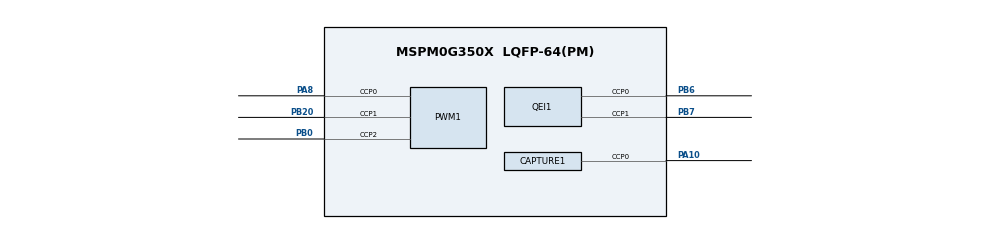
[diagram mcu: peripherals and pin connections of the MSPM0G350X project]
/**
 * @cliArgs --device "MSPM0G350X" --part "Default" --package "LQFP-64(PM)" --product "mspm0_sdk@2.06.00.05"
 * @versions {"tool":"1.21.0+3721"}
 */

/**
 * Import the modules used in this configuration.
 */
const CAPTURE  = scripting.addModule("/ti/driverlib/CAPTURE", {}, false);
const CAPTURE1 = CAPTURE.addInstance();
const GPIO     = scripting.addModule("/ti/driverlib/GPIO", {}, false);
const GPIO1    = GPIO.addInstance();
const GPIO2    = GPIO.addInstance();
const GPIO3    = GPIO.addInstance();
const GPIO4    = GPIO.addInstance();
const PWM      = scripting.addModule("/ti/driverlib/PWM", {}, false);
const PWM1     = PWM.addInstance();
const QEI      = scripting.addModule("/ti/driverlib/QEI", {}, false);
const QEI1     = QEI.addInstance();
const SYSCTL   = scripting.addModule("/ti/driverlib/SYSCTL");
const TIMER    = scripting.addModule("/ti/driverlib/TIMER", {}, false);
const TIMER1   = TIMER.addInstance();

/**
 * Write custom configuration values to the imported modules.
 */
CAPTURE1.$name                       = "CAPTURE_0";
CAPTURE1.multi_countMode             = "DL_TIMER_COUNT_MODE_UP_DOWN";
CAPTURE1.ccIndexMulti                = [0];
CAPTURE1.multi_ch0_input_mode        = "DL_TIMER_CC_IN_SEL_TRIG";
CAPTURE1.multi_ch0_captEdgeDetection = "DL_TIMER_CC_CCOND_TRIG_EDGE";
CAPTURE1.captMode                    = "PERIOD_CAPTURE_UP";
CAPTURE1.captEdgeDetection           = "EDGE";
CAPTURE1.peripheral.ccp0Pin.$assign  = "PA10";
CAPTURE1.ccp0PinConfig.$name         = "ti_driverlib_gpio_GPIOPinGeneric6";

const Board = scripting.addModule("/ti/driverlib/Board", {}, false);

GPIO1.port                           = "PORTA";
GPIO1.$name                          = "GPIO_OLED_13";
GPIO1.associatedPins.create(2);
GPIO1.associatedPins[0].$name        = "GPIO_SCK";
GPIO1.associatedPins[0].initialValue = "SET";
GPIO1.associatedPins[0].assignedPin  = "31";
GPIO1.associatedPins[1].$name        = "GPIO_SDA";
GPIO1.associatedPins[1].assignedPin  = "28";
GPIO1.associatedPins[1].initialValue = "SET";

GPIO2.$name                         = "GPIO_LEDS";
GPIO2.port                          = "PORTA";
GPIO2.associatedPins[0].$name       = "LED_1";
GPIO2.associatedPins[0].assignedPin = "0";

GPIO3.$name                                 = "GPIO_EC11";
GPIO3.associatedPins[0].direction           = "INPUT";
GPIO3.associatedPins[0].assignedPin         = "18";
GPIO3.associatedPins[0].assignedPort        = "PORTA";
GPIO3.associatedPins[0].$name               = "SW";
GPIO3.associatedPins[0].assignedPortSegment = "Upper";
GPIO3.associatedPins[0].interruptEn         = true;
GPIO3.associatedPins[0].polarity            = "RISE_FALL";

GPIO4.$name                          = "GPIO";
GPIO4.associatedPins[0].assignedPort = "PORTB";
GPIO4.associatedPins[0].assignedPin  = "23";
GPIO4.associatedPins[0].$name        = "BUZZER";

PWM1.ccIndex                            = [0,1,2];
PWM1.$name                              = "LED_rgb";
PWM1.timerStartTimer                    = true;
PWM1.clockDivider                       = 2;
PWM1.peripheral.$assign                 = "TIMA0";
PWM1.peripheral.ccp0Pin.$assign         = "PA8";
PWM1.peripheral.ccp1Pin.$assign         = "PB20";
PWM1.peripheral.ccp2Pin.$assign         = "PB0";
PWM1.PWM_CHANNEL_0.$name                = "ti_driverlib_pwm_PWMTimerCC0";
PWM1.PWM_CHANNEL_0.dutyCycle            = 50;
PWM1.PWM_CHANNEL_0.invert               = true;
PWM1.PWM_CHANNEL_1.$name                = "ti_driverlib_pwm_PWMTimerCC1";
PWM1.PWM_CHANNEL_1.invert               = true;
PWM1.ccp0PinConfig.direction            = scripting.forceWrite("OUTPUT");
PWM1.ccp0PinConfig.hideOutputInversion  = scripting.forceWrite(false);
PWM1.ccp0PinConfig.onlyInternalResistor = scripting.forceWrite(false);
PWM1.ccp0PinConfig.passedPeripheralType = scripting.forceWrite("Digital");
PWM1.ccp0PinConfig.$name                = "ti_driverlib_gpio_GPIOPinGeneric1";
PWM1.ccp1PinConfig.direction            = scripting.forceWrite("OUTPUT");
PWM1.ccp1PinConfig.hideOutputInversion  = scripting.forceWrite(false);
PWM1.ccp1PinConfig.onlyInternalResistor = scripting.forceWrite(false);
PWM1.ccp1PinConfig.passedPeripheralType = scripting.forceWrite("Digital");
PWM1.ccp1PinConfig.$name                = "ti_driverlib_gpio_GPIOPinGeneric2";
PWM1.PWM_CHANNEL_2.$name                = "ti_driverlib_pwm_PWMTimerCC2";
PWM1.PWM_CHANNEL_2.invert               = true;
PWM1.ccp2PinConfig.direction            = scripting.forceWrite("OUTPUT");
PWM1.ccp2PinConfig.hideOutputInversion  = scripting.forceWrite(false);
PWM1.ccp2PinConfig.onlyInternalResistor = scripting.forceWrite(false);
PWM1.ccp2PinConfig.passedPeripheralType = scripting.forceWrite("Digital");
PWM1.ccp2PinConfig.$name                = "ti_driverlib_gpio_GPIOPinGeneric3";

QEI1.$name                              = "TIMER_QEI";
QEI1.interrupts                         = ["ZERO_EVENT"];
QEI1.retentionRestoreCnt                = true;
QEI1.enableIndexInput                   = true;
QEI1.peripheral.$assign                 = "TIMG8";
QEI1.peripheral.ccp0Pin.$assign         = "PB6";
QEI1.peripheral.ccp1Pin.$assign         = "PB7";
QEI1.ccp0PinConfig.hideOutputInversion  = scripting.forceWrite(false);
QEI1.ccp0PinConfig.onlyInternalResistor = scripting.forceWrite(false);
QEI1.ccp0PinConfig.passedPeripheralType = scripting.forceWrite("Digital");
QEI1.ccp0PinConfig.$name                = "ti_driverlib_gpio_GPIOPinGeneric0";
QEI1.ccp1PinConfig.hideOutputInversion  = scripting.forceWrite(false);
QEI1.ccp1PinConfig.onlyInternalResistor = scripting.forceWrite(false);
QEI1.ccp1PinConfig.passedPeripheralType = scripting.forceWrite("Digital");
QEI1.ccp1PinConfig.$name                = "ti_driverlib_gpio_GPIOPinGeneric4";
QEI1.ccp1PinConfig.enableConfig         = true;
QEI1.idxPinConfig.$name                 = "ti_driverlib_gpio_GPIOPinGeneric5";

SYSCTL.forceDefaultClkConfig = true;
SYSCTL.clockTreeEn           = true;

TIMER1.timerPeriod        = "1 ms";
TIMER1.interrupts         = ["ZERO"];
TIMER1.$name              = "TIMER_MS";
TIMER1.timerMode          = "PERIODIC_UP";
TIMER1.peripheral.$assign = "TIMG12";

/**
 * Pinmux solution for unlocked pins/peripherals. This ensures that minor changes to the automatic solver in a future
 * version of the tool will not impact the pinmux you originally saw.  These lines can be completely deleted in order to
 * re-solve from scratch.
 */
CAPTURE1.peripheral.$suggestSolution         = "TIMA1";
Board.peripheral.$suggestSolution            = "DEBUGSS";
Board.peripheral.swclkPin.$suggestSolution   = "PA20";
Board.peripheral.swdioPin.$suggestSolution   = "PA19";
GPIO1.associatedPins[0].pin.$suggestSolution = "PA31";
GPIO1.associatedPins[1].pin.$suggestSolution = "PA28";
GPIO2.associatedPins[0].pin.$suggestSolution = "PA0";
GPIO3.associatedPins[0].pin.$suggestSolution = "PA18";
GPIO4.associatedPins[0].pin.$suggestSolution = "PB23";
QEI1.peripheral.idxPin.$suggestSolution      = "PA1";
